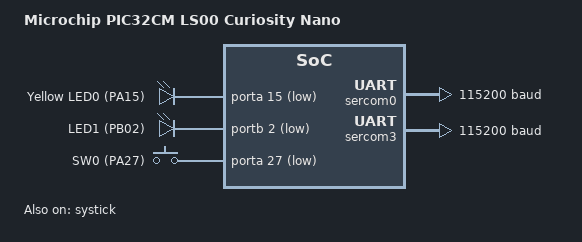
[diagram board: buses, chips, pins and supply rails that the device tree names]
/*
 * Copyright (c) 2026 Microchip Technology Inc.
 *
 * SPDX-License-Identifier: Apache-2.0
 */

/dts-v1/;

#include <microchip/pic32c/pic32cm_ls/pic32cm_ls00/pic32cm5164ls00048.dtsi>
#include <zephyr/dt-bindings/gpio/gpio.h>
#include "pic32cm_ls00_cnano-pinctrl.dtsi"

/ {
	model = "Microchip PIC32CM LS00 Curiosity Nano";
	compatible = "microchip,pic32cm-ls00-cnano", "microchip,pic32cm5164ls00048";

	chosen {
		zephyr,sram = &sram0;
		zephyr,flash = &flash0;
		zephyr,systick = &systick;
		
		zephyr,console = &sercom3;
		zephyr,shell-uart = &sercom3;
	};

	aliases {
		led0 = &led0;
		led1 = &led1;
		sw0 = &button0;
	};

	leds {
		compatible = "gpio-leds";

		led0: led_0 {
			gpios = <&porta 15 GPIO_ACTIVE_LOW>;
			label = "Yellow LED0 (PA15)";
		};

		led1: led_1 {
			gpios = <&portb 2 GPIO_ACTIVE_LOW>;
			label = "LED1 (PB02)";
		};
	};

	buttons {
		compatible = "gpio-keys";

		button0: button_0 {
			gpios = <&porta 27 (GPIO_PULL_UP | GPIO_ACTIVE_LOW)>;
			label = "SW0 (PA27)";
		};
	};
};

&cpu0 {
	clock-frequency = <48000000>;
};

&systick {
	status = "okay";
};

&porta {
	status = "okay";
};

&portb {
	status = "okay";
};

&sercom0 {
	compatible = "microchip,sercom-g1-uart";
	current-speed = <115200>;
	data-bits = <8>;
	parity = "none";
	stop-bits = "1";
	rxpo = <1>; /* RX on PAD[1] (PA23) */
	txpo = <0>; /* TX on PAD[0] (PA22) */
	pinctrl-0 = <&sercom0_uart_default>;
	pinctrl-names = "default";
	status = "okay";
};


&sercom3 {
	compatible = "microchip,sercom-g1-uart";
	current-speed = <115200>;
	data-bits = <8>;
	parity = "none";
	stop-bits = "1";
	rxpo = <1>; /* RX on PAD[1] (PB09) */
	txpo = <0>; /* TX on PAD[0] (PB08) */
	pinctrl-0 = <&sercom3_uart_default>;
	pinctrl-names = "default";
	status = "okay";
};
